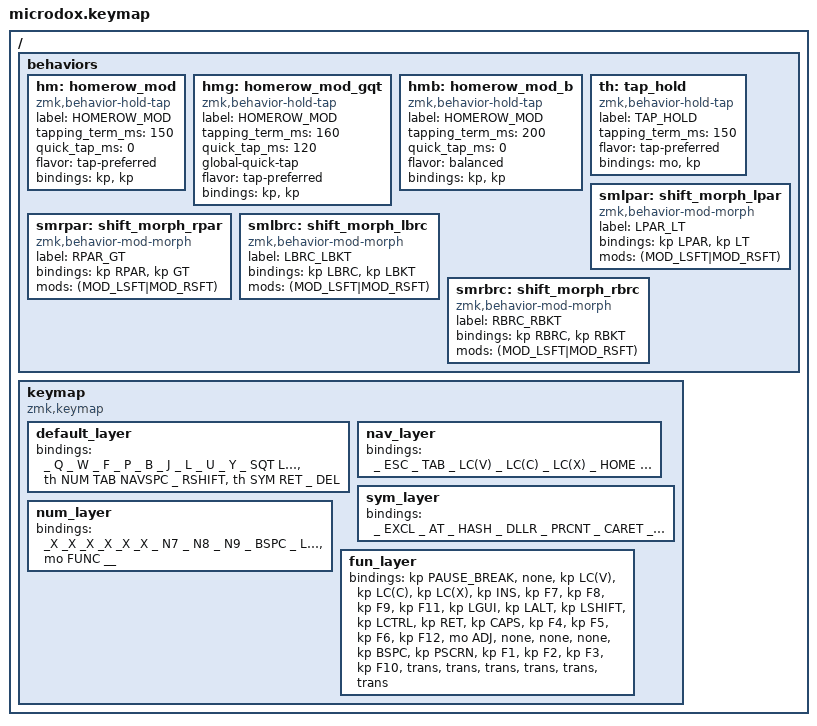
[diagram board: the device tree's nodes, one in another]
/*
 * Copyright (c) 2020 The ZMK Contributors
 *
 * SPDX-License-Identifier: MIT
 */

#include <behaviors.dtsi>
#include <dt-bindings/zmk/keys.h>
#include <dt-bindings/zmk/bt.h>

#define BASE 0
#define NAV 1
#define SYM 2
#define NUM 3
#define FUNC 4

#define _ &kp
#define __ &trans
#define _X &none

#define WINR LC(LG(RIGHT))
#define WINL LC(LG(LEFT))
#define CC LC(C)
#define CX LC(X)
#define CP LC(V)
#define PT LC(LS(TAB))
#define NT LC(TAB)

#define LST(tapcode) &hmg LSHIFT tapcode
#define RST(tapcode) &hmg RSHIFT tapcode
#define LCT(tapcode) &hmg LCTRL tapcode
#define RCT(tapcode) &hmg RCTRL tapcode
#define LAT(tapcode) &hmg LALT tapcode
#define RAT(tapcode) &hmg RALT tapcode
#define LGT(tapcode) &hmg LGUI tapcode
#define RGT(tapcode) &hmg RGUI tapcode
#define NAVSPC &lt NAV SPACE

#define LPLT &smlpar 
#define RPRT &smrpar 
#define LB &smlbrc 
#define RB &smrbrc 

// Key Positions 
//  0   1   2   3   4       5   6   7   8   9
//  10  11  12  13  14      15  16  17  18  19
//  20  21  22  23  24      25  26  27  28  29
//          30  31  32      33  34  35

/ {

    behaviors {
        hm: homerow_mod {
            compatible = "zmk,behavior-hold-tap";
            label = "HOMEROW_MOD";
            #binding-cells = <2>;
            tapping_term_ms = <150>;
            quick_tap_ms = <0>;
            flavor = "tap-preferred";
            bindings = <&kp>, <&kp>;
        };

        hmg: homerow_mod_gqt {
            compatible = "zmk,behavior-hold-tap";
            label = "HOMEROW_MOD";
            #binding-cells = <2>;
            tapping_term_ms = <160>;
            quick_tap_ms = <120>;
            global-quick-tap;
            flavor = "tap-preferred";
            bindings = <&kp>, <&kp>;
        };

        hmb: homerow_mod_b {
            compatible = "zmk,behavior-hold-tap";
            label = "HOMEROW_MOD";
            #binding-cells = <2>;
            tapping_term_ms = <200>;
            quick_tap_ms = <0>;
            flavor = "balanced";
            bindings = <&kp>, <&kp>;
        };

        th: tap_hold {
            compatible = "zmk,behavior-hold-tap";
            label = "TAP_HOLD";
            #binding-cells = <2>;
            tapping_term_ms = <150>;
            flavor = "tap-preferred";
            bindings = <&mo>, <&kp>;
        };

        smlpar: shift_morph_lpar {
            compatible = "zmk,behavior-mod-morph";
            label = "LPAR_LT";
            #binding-cells = <0>;
            bindings = <&kp LPAR>, <&kp LT>;
            mods = <(MOD_LSFT|MOD_RSFT)>;
        };

        smrpar: shift_morph_rpar {
            compatible = "zmk,behavior-mod-morph";
						label = "RPAR_GT";
            #binding-cells = <0>;
            bindings = <&kp RPAR>, <&kp GT>;
            mods = <(MOD_LSFT|MOD_RSFT)>;
        };

        smlbrc: shift_morph_lbrc {
            compatible = "zmk,behavior-mod-morph";
						label = "LBRC_LBKT";
            #binding-cells = <0>;
            bindings = <&kp LBRC>, <&kp LBKT>;
            mods = <(MOD_LSFT|MOD_RSFT)>;
        };

        smrbrc: shift_morph_rbrc {
            compatible = "zmk,behavior-mod-morph";
						label = "RBRC_RBKT";
            #binding-cells = <0>;
            bindings = <&kp RBRC>, <&kp RBKT>;
            mods = <(MOD_LSFT|MOD_RSFT)>;
        };
    };

    keymap {
            compatible = "zmk,keymap";

            default_layer {

// Base Layer: Colemak
//
// ,----------------------------------.        ,----------------------------------.
// |   Q  |   W  |   F  |   P  |   B  |        |   J  |   L  |   U  |   Y  | '  " |
// |      |      |      |      |      |        |      |      |      |      |      |
// |------+------+------+------+------|        |------+------+------+------+------|
// |   A  |   R  |   S  |   T  |   G  |        |   M  |   N  |   E  |   I  |   O  |
// |  GUI |  ALT | SHFT | CTRL |      |        |      | CTRL | SHFT |  ALT |  GUI |
// |------+------+------+------+------|        |------+------+------+------+------|
// |   Z  |   X  |   C  |   D  |   V  |        |   K  |   H  | ,  < | .  > | /  ? |
// | SHFT |      |      |      |      |        |      |      |      |      | SHFT |
// `------+------+------+------+------|        |------+------+------+------+------'
//               | ESC  | TAB  | SPC  |        | BSP  | RET  | DEL  |
//               |      | NUM  | NAV  |        | SYM  | LNUM |      |
//               `--------------------'        `--------------------'
//

                bindings = <
        _ Q     _ W       _ F     _ P           _ B        /**/     _ J       _ L          _ U       _ Y       _ SQT    
		LGT(A)  LAT(R)    LST(S)  LCT(T)        _ G        /**/     _ M       RCT(N)       RST(E)    LAT(I)    RGT(O)   
		LST(Z)  RAT(X)    _ C     _ D           _ V        /**/     _ K       _ H          _ COMMA   RAT(DOT)  RST(FSLH)
			              _ ESC   &th NUM TAB   NAVSPC     /**/     _ RSHIFT  &th SYM RET  _ DEL    
			>;
        };
        nav_layer {

// Navigation Layer
//		- Also contains some single-hand shortcuts for basic functions 
//
// ,----------------------------------.        ,----------------------------------.
// | ESC  |      | PAST | COPY | CUT  |        | HOME | PGUP | PGDN | END  | BSPC |
// |      |      |      |      |      |        |      |      |      |      |      |
// |------+------+------+------+------|        |------+------+------+------+------|
// |      |      |      |      | RET  |        | LEFT | DOWN |  UP  | RGHT | RET  |
// | GUI  | ALT  | SHFT | CTRL |      |        |      |      |      |      |      |
// |------+------+------+------+------|        |------+------+------+------+------|
// |      |      |      |      |      |        |      | <-D  |      | D->  | DEL  |
// |      |      |      |      |      |        |      |      |      |      |      |
// `-------------+------+------+------|        |------+------+------+-------------'
//               |      |      |      |        |      |      |      |
//               |      |      |      |        |      |      |      |
//               `--------------------'        `--------------------'
//
             bindings = <
    _ ESC   _ TAB   _ LC(V)   _ LC(C)  _ LC(X)   /**/    _ HOME    _ PG_DN   _ PG_UP  _ END    _ BSPC  
    _ LGUI  _ LALT  _ LSHIFT  _ LCTRL  _ RET     /**/    _ LEFT    _ DOWN    _ UP     _ RIGHT  _ RET   
    _ DEL   _X      _X        _X       _X        /**/    _X       _X         _X       _X       _ DEL   
                    __        __       __        /**/    __       __         __
            >;
        };

        sym_layer {

// Symbol Layer
//		- Lots of WIP here
//		- But the Frey seems like the easiest to start with
//		- Then I sort of filled in gaps, planning on a 5 column layout
//
// ,----------------------------------.        ,----------------------------------.
// |  !   |  @   |  #   |  $   |  %   |        |  ^   |  &   |  *   |  |   |  \   |
// |      |      |      |      |      |        |      |      |      |      |      |
// |------+------+------+------+------|        |------+------+------+------+------|
// | `  ~ |  {   |  (   |  )   |  }   |        |      | =  + | -  _ |  :   | ;  : |
// | GUI  | ALT  | SHFT | CTRL |      |        |      | CTRL | SHFT | ALT  | GUI  |
// |------+------+------+------+------|        |------+------+------+------+------|
// |  ~   |  <   |  [   |  ]   |  >   |        |      |  +   |  _   |      |  /   |
// |      |      |      |      |      |        |      |      |      |      |      |
// `-------------+------+------+------|        |------+------+------+-------------'
//               |      |      |      |        |      |      |      |
//               |      |      |      |        |      |      |      |
//               `--------------------'        `--------------------'
//
                bindings = <
     _ EXCL     _ AT     _ HASH    _ DLLR    _ PRCNT  /**/   _ CARET  _ AMPS   _ ASTRK   _ PIPE  _ BSLH  
     LB         LPLT     _ EQUAL   RPRT      _ RB     /**/   _X       _ LCTRL  _ LSHIFT  _ LALT  _ LGUI  
     _ GRAVE    _ TILDE  _ UNDER   _X        _X       /**/   _X       _ MINUS  _ PLUS    _ COLON _ SEMI  
                         __        __        __       /**/   __       __       __
            >;
        };

        num_layer {
//
// Numrow + Pad layer
//
// ,----------------------------------.         ,----------------------------------.
// | 1  ! | 2  @ | 3  # | 4  $ | 5  % |         | 6  ^ | 7  & | 8  * | 9  ( | 0  ) |
// |      |      |      |      |      |         |      |      |      |      |      |
// |------+------+------+------+------|         |------+------+------+------+------|
// |      |      |  .   |  =   |      |         |  -   | 4  $ | 5  % | 6  ^ |  *   |
// | GUI  | ALT  | SHFT | CTRL |      |         |      |      |      |      |      |
// |------+------+------+------+------|         |------+------+------+------+------|
// |      |      |      |      |      |         |  _   | 1  ! | 2  @ | 3  # |  /   |
// |      |      |      |      |      |         |      |      |      |      |      |
// `-------------+------+------+------|         |------+------+------+-------------'
//               |      |      |      |         | BSPC | RET  | DEL  |
//               |      |      |      |         |      |      |      |
//               `--------------------'         `--------------------'
//
            bindings = <
    _X      _X     _X        _X      _X   /**/   _X    _ N7      _ N8  _ N9  _ BSPC 
    _ LGUI  _ LALT _ LSHIFT  _ LCTRL _X   /**/   _X    _ N4      _ N5  _ N6  _ RET  
    _X      _X     _X        _X      _X   /**/   _X    _ N1      _ N2  _ N3  _ DOT  
                   __        __      __   /**/   _ N0  &mo FUNC  __
            >;
        };            

            fun_layer {
//
// F-Key Layer
// + Left hand shortcuts
//
// ,----------------------------------.         ,----------------------------------.
// | Brk  |      | Past | Copy | Cut  |         | Ins  |  F7  |  F8  |  F9  |  F11 |
// |      |      |      |      |      |         |      |      |      |      |      |
// |------+------+------+------+------|         |------+------+------+------+------|
// |      |      |      |      | Ret  |         | Caps |  F4  |  F5  |  F6  |  F12 |
// | GUI  | Alt  | Shft | Ctrl |      |         |      |      |      |      |      |
// |------+------+------+------+------|         |------+------+------+------+------|
// |      |      |      |      | Bspc |         | Prt  |  F1  |  F2  |  F3  |  F10 |
// |      |      |      |      |      |         |      |      |      |      |      |
// `-------------+------+------+------|         |------+------+------+-------------'
//               |      |      |      |         |      |      |      |
//               |      |      |      |         |      |      |      |
//               `--------------------'         `--------------------'
                bindings = <
    &kp PAUSE_BREAK  &none     &kp LC(V)  &kp LC(C)  &kp LC(X)       &kp INS    &kp F7   &kp F8   &kp F9   &kp F11
    &kp LGUI         &kp LALT  &kp LSHIFT &kp LCTRL  &kp RET         &kp CAPS   &kp F4   &kp F5   &kp F6   &kp F12
    &mo ADJ          &none     &none      &none      &kp BSPC        &kp PSCRN  &kp F1   &kp F2   &kp F3   &kp F10
                               &trans     &trans     &trans          &trans     &trans   &trans
                >;
            };

//              blank_layer {
//
// Layer Template
//
// ,----------------------------------.         ,----------------------------------.
// |      |      |      |      |      |         |      |      |      |      |      |
// |      |      |      |      |      |         |      |      |      |      |      |
// |------+------+------+------+------|         |------+------+------+------+------|
// |      |      |      |      |      |         |      |      |      |      |      |
// | GUI  | ALT  | SHFT | CTRL |      |         |      |      |      |      |      |
// |------+------+------+------+------|         |------+------+------+------+------|
// |      |      |      |      |      |         |      |      |      |      |      |
// |      |      |      |      |      |         |      |      |      |      |      |
// `-------------+------+------+------|         |------+------+------+-------------'
//               |      |      |      |         |      |      |      |
//               |      |      |      |         |      |      |      |
//               `--------------------'         `--------------------'
//
//                      bindings = <
//              &none &none &none &none &none    &none &none &none &none &none
//              &none &none &none &none &none    &none &none &none &none &none
//              &none &none &none &none &none    &none &none &none &none &none
//                          &none &none &none    &none &none &none 
//                      >;
//              };

        };
};
